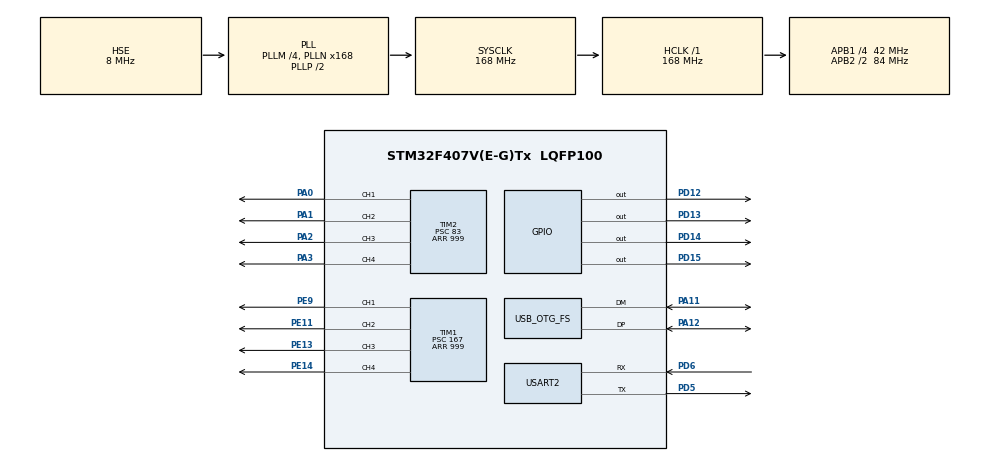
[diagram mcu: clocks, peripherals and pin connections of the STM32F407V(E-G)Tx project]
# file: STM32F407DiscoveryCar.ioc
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FREERTOS.Tasks01=defaultTask,24,128,StartDefaultTask,Default,NULL,Dynamic,NULL,NULL
FREERTOS.configENABLE_FPU=1
Mcu.Family=STM32F4
Mcu.Name=STM32F407V(E-G)Tx
Mcu.Package=LQFP100
NVIC.OTG_FS_IRQn=true\:5\:0\:false\:false\:true\:true\:false\:true
NVIC.PriorityGroup=NVIC_PRIORITYGROUP_4
NVIC.TIM3_IRQn=true\:15\:0\:false\:false\:true\:false\:false\:true
NVIC.TimeBase=TIM3_IRQn
NVIC.TimeBaseIP=TIM3
PA0-WKUP.Signal=S_TIM2_CH1_ETR
PA1.Signal=S_TIM2_CH2
PA11.Mode=Device_Only
PA11.Signal=USB_OTG_FS_DM
PA12.Mode=Device_Only
PA12.Signal=USB_OTG_FS_DP
PA2.Signal=S_TIM2_CH3
PA3.Signal=S_TIM2_CH4
PD12.Signal=GPIO_Output
PD13.Signal=GPIO_Output
PD14.Signal=GPIO_Output
PD15.Signal=GPIO_Output
PD5.Mode=Asynchronous
PD5.Signal=USART2_TX
PD6.Mode=Asynchronous
PD6.Signal=USART2_RX
PE11.Signal=S_TIM1_CH2
PE13.Signal=S_TIM1_CH3
PE14.Signal=S_TIM1_CH4
PE9.Signal=S_TIM1_CH1
PH0-OSC_IN.Mode=HSE-External-Oscillator
PH0-OSC_IN.Signal=RCC_OSC_IN
PH1-OSC_OUT.Mode=HSE-External-Oscillator
PH1-OSC_OUT.Signal=RCC_OSC_OUT
ProjectManager.HeapSize=0x200
ProjectManager.StackSize=0x400
ProjectManager.TargetToolchain=Makefile
RCC.48MHZClocksFreq_Value=48000000
RCC.AHBFreq_Value=168000000
RCC.APB1CLKDivider=RCC_HCLK_DIV4
RCC.APB1Freq_Value=42000000
RCC.APB1TimFreq_Value=84000000
RCC.APB2CLKDivider=RCC_HCLK_DIV2
RCC.APB2Freq_Value=84000000
RCC.APB2TimFreq_Value=168000000
RCC.CortexFreq_Value=168000000
RCC.HCLKFreq_Value=168000000
RCC.HSE_VALUE=8000000
RCC.HSI_VALUE=16000000
RCC.LSE_VALUE=32768
RCC.PLLM=4
RCC.PLLN=168
RCC.PLLQ=7
RCC.SYSCLKFreq_VALUE=168000000
RCC.SYSCLKSource=RCC_SYSCLKSOURCE_PLLCLK
RCC.VCOOutputFreq_Value=336000000
SH.S_TIM1_CH1.0=TIM1_CH1,PWM Generation1 CH1
SH.S_TIM1_CH2.0=TIM1_CH2,PWM Generation2 CH2
SH.S_TIM1_CH3.0=TIM1_CH3,PWM Generation3 CH3
SH.S_TIM1_CH4.0=TIM1_CH4,PWM Generation4 CH4
SH.S_TIM2_CH1_ETR.0=TIM2_CH1,PWM Generation1 CH1
SH.S_TIM2_CH2.0=TIM2_CH2,PWM Generation2 CH2
SH.S_TIM2_CH3.0=TIM2_CH3,PWM Generation3 CH3
SH.S_TIM2_CH4.0=TIM2_CH4,PWM Generation4 CH4
TIM1.AutoReloadPreload=TIM_AUTORELOAD_PRELOAD_ENABLE
TIM1.Channel-PWM\ Generation1\ CH1=TIM_CHANNEL_1
TIM1.Channel-PWM\ Generation2\ CH2=TIM_CHANNEL_2
TIM1.Channel-PWM\ Generation3\ CH3=TIM_CHANNEL_3
TIM1.Channel-PWM\ Generation4\ CH4=TIM_CHANNEL_4
TIM1.Period=999
TIM1.Prescaler=167
TIM2.AutoReloadPreload=TIM_AUTORELOAD_PRELOAD_ENABLE
TIM2.Channel-PWM\ Generation1\ CH1=TIM_CHANNEL_1
TIM2.Channel-PWM\ Generation2\ CH2=TIM_CHANNEL_2
TIM2.Channel-PWM\ Generation3\ CH3=TIM_CHANNEL_3
TIM2.Channel-PWM\ Generation4\ CH4=TIM_CHANNEL_4
TIM2.Period=999
TIM2.Prescaler=83
USART2.VirtualMode=VM_ASYNC
USB_DEVICE.CLASS_NAME_FS=CDC
USB_DEVICE.PRODUCT_STRING_CDC_FS=STM32F407DiscoveryCar
USB_DEVICE.VirtualMode-CDC_FS=Cdc
USB_DEVICE.VirtualModeFS=Cdc_FS
USB_OTG_FS.VirtualMode=Device_Only
VP_FREERTOS_VS_CMSIS_V2.Mode=CMSIS_V2
VP_SYS_VS_tim3.Mode=TIM3
VP_USB_DEVICE_VS_USB_DEVICE_CDC_FS.Mode=CDC_FS
board=custom

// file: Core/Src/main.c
/* USER CODE BEGIN Header */
/**
  ******************************************************************************
  * @file           : main.c
  * @brief          : Main program body
  ******************************************************************************
  * @attention
  *
  * <h2><center>&copy; Copyright (c) 2022 STMicroelectronics.
  * All rights reserved.</center></h2>
  *
  * This software component is licensed by ST under BSD 3-Clause license,
  * the "License"; You may not use this file except in compliance with the
  * License. You may obtain a copy of the License at:
  *                        opensource.org/licenses/BSD-3-Clause
  *
  ******************************************************************************
  */
/* USER CODE END Header */
#include "main.h"
#include "cmsis_os.h"
#include "tim.h"
#include "usart.h"
#include "usb_device.h"
#include "gpio.h"

/* USER CODE BEGIN Includes */
#include "car_driver.h"
#include "config.h"
#include "usbd_cdc_if.h"
#include "debug.h"
/* USER CODE END Includes */

void SystemClock_Config(void);
void MX_FREERTOS_Init(void);

int main(void)
{

  /* MCU Configuration--------------------------------------------------------*/

  /* Reset of all peripherals, Initializes the Flash interface and the Systick. */
  HAL_Init();

  /* Configure the system clock */
  SystemClock_Config();

  /* Initialize all configured peripherals */
  MX_GPIO_Init();
  MX_TIM1_Init();
  MX_USART2_UART_Init();
  MX_TIM2_Init();
  /* USER CODE BEGIN 2 */
  motorInit();
  // carStart();
  // carMove(15000, FRONT);
  // HAL_Delay(500);
  // carStop();

  /* USER CODE END 2 */

  /* Init scheduler */
  osKernelInitialize();  /* Call init function for freertos objects (in freertos.c) */
  MX_FREERTOS_Init();
  /* Start scheduler */
  osKernelStart();

  /* We should never get here as control is now taken by the scheduler */
  /* Infinite loop */
  while (1)
  {

  }
}

void SystemClock_Config(void)
{
  RCC_OscInitTypeDef RCC_OscInitStruct = {0};
  RCC_ClkInitTypeDef RCC_ClkInitStruct = {0};

  /** Configure the main internal regulator output voltage
  */
  __HAL_RCC_PWR_CLK_ENABLE();
  __HAL_PWR_VOLTAGESCALING_CONFIG(PWR_REGULATOR_VOLTAGE_SCALE1);
  /** Initializes the RCC Oscillators according to the specified parameters
  * in the RCC_OscInitTypeDef structure.
  */
  RCC_OscInitStruct.OscillatorType = RCC_OSCILLATORTYPE_HSE;
  RCC_OscInitStruct.HSEState = RCC_HSE_ON;
  RCC_OscInitStruct.PLL.PLLState = RCC_PLL_ON;
  RCC_OscInitStruct.PLL.PLLSource = RCC_PLLSOURCE_HSE;
  RCC_OscInitStruct.PLL.PLLM = 4;
  RCC_OscInitStruct.PLL.PLLN = 168;
  RCC_OscInitStruct.PLL.PLLP = RCC_PLLP_DIV2;
  RCC_OscInitStruct.PLL.PLLQ = 7;
  if (HAL_RCC_OscConfig(&RCC_OscInitStruct) != HAL_OK)
  {
    Error_Handler();
  }
  /** Initializes the CPU, AHB and APB buses clocks
  */
  RCC_ClkInitStruct.ClockType = RCC_CLOCKTYPE_HCLK|RCC_CLOCKTYPE_SYSCLK
                              |RCC_CLOCKTYPE_PCLK1|RCC_CLOCKTYPE_PCLK2;
  RCC_ClkInitStruct.SYSCLKSource = RCC_SYSCLKSOURCE_PLLCLK;
  RCC_ClkInitStruct.AHBCLKDivider = RCC_SYSCLK_DIV1;
  RCC_ClkInitStruct.APB1CLKDivider = RCC_HCLK_DIV4;
  RCC_ClkInitStruct.APB2CLKDivider = RCC_HCLK_DIV2;

  if (HAL_RCC_ClockConfig(&RCC_ClkInitStruct, FLASH_LATENCY_5) != HAL_OK)
  {
    Error_Handler();
  }
}

void HAL_TIM_PeriodElapsedCallback(TIM_HandleTypeDef *htim)
{
  if (htim->Instance == TIM3) {
    HAL_IncTick();
  }
}

void Error_Handler(void)
{
  __disable_irq();
  while (1)
  {
  }
}

/************************ (C) COPYRIGHT STMicroelectronics *****END OF FILE****/

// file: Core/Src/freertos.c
/* USER CODE BEGIN Header */
/**
  ******************************************************************************
  * File Name          : freertos.c
  * Description        : Code for freertos applications
  ******************************************************************************
  * @attention
  *
  * <h2><center>&copy; Copyright (c) 2022 STMicroelectronics.
  * All rights reserved.</center></h2>
  *
  * This software component is licensed by ST under Ultimate Liberty license
  * SLA0044, the "License"; You may not use this file except in compliance with
  * the License. You may obtain a copy of the License at:
  *                             www.st.com/SLA0044
  *
  ******************************************************************************
  */
/* USER CODE END Header */

#include "FreeRTOS.h"
#include "task.h"
#include "main.h"
#include "cmsis_os.h"

/* USER CODE BEGIN Includes */
#include "system.h"
/* USER CODE END Includes */

/* Definitions for defaultTask */
osThreadId_t defaultTaskHandle;
const osThreadAttr_t defaultTask_attributes = {
  .name = "defaultTask",
  .stack_size = 128 * 4,
  .priority = (osPriority_t) osPriorityNormal,
};

void StartDefaultTask(void *argument);

extern void MX_USB_DEVICE_Init(void);
void MX_FREERTOS_Init(void); /* (MISRA C 2004 rule 8.1) */

void MX_FREERTOS_Init(void) {
  /* USER CODE BEGIN Init */
  systemLaunch();
  /* USER CODE END Init */

  /* Create the thread(s) */
  /* creation of defaultTask */
  defaultTaskHandle = osThreadNew(StartDefaultTask, NULL, &defaultTask_attributes);

}

void StartDefaultTask(void *argument)
{
  /* init code for USB_DEVICE */
  MX_USB_DEVICE_Init();
  /* USER CODE BEGIN StartDefaultTask */
  /* Infinite loop */
  for(;;)
  {
    HAL_GPIO_TogglePin(GPIOD, GPIO_PIN_12);
    HAL_GPIO_TogglePin(GPIOD, GPIO_PIN_13);
    HAL_GPIO_TogglePin(GPIOD, GPIO_PIN_14);
    HAL_GPIO_TogglePin(GPIOD, GPIO_PIN_15);
    osDelay(500);
  }
  /* USER CODE END StartDefaultTask */
}

/************************ (C) COPYRIGHT STMicroelectronics *****END OF FILE****/
